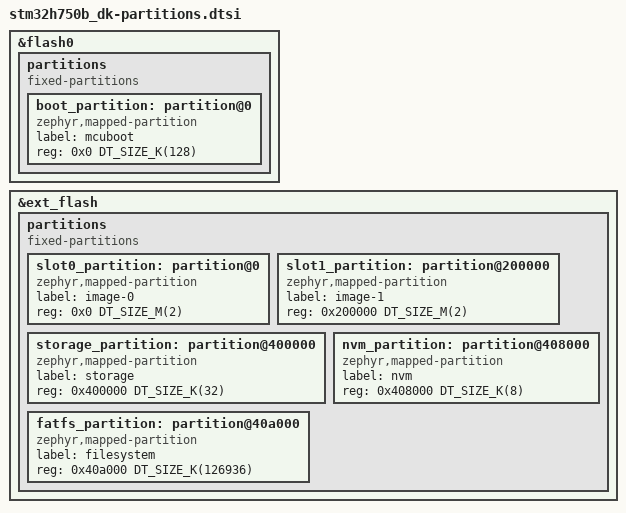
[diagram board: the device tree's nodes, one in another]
/* Partition layout for stm32h750b_dk: the flash memory map shared by the
 * bootloader and every application image. Generated by
 * tools/partition_layout.py; do not edit by hand -- re-run
 * `python3 tools/partition_layout.py --fix stm32h750b_dk` after changing
 * the upstream board geometry or tools/boards.toml.
 *
 * Board-specific overlay glue (delete-nodes, device enablement,
 * aliases/chosen) lives in dts/st/stm32h750b_dk.dtsi, which includes
 * this file.
 */

&flash0 {
	partitions {
		compatible = "fixed-partitions";
		#address-cells = <1>;
		#size-cells = <1>;
		ranges;

		boot_partition: partition@0 {
			compatible = "zephyr,mapped-partition";
			label = "mcuboot";
			reg = <0x0 DT_SIZE_K(128)>;
		};
	};
};

&ext_flash {
	partitions {
		compatible = "fixed-partitions";
		#address-cells = <1>;
		#size-cells = <1>;
		ranges;

		slot0_partition: partition@0 {
			compatible = "zephyr,mapped-partition";
			label = "image-0";
			reg = <0x0 DT_SIZE_M(2)>;
		};

		slot1_partition: partition@200000 {
			compatible = "zephyr,mapped-partition";
			label = "image-1";
			reg = <0x200000 DT_SIZE_M(2)>;
		};

		storage_partition: partition@400000 {
			compatible = "zephyr,mapped-partition";
			label = "storage";
			reg = <0x400000 DT_SIZE_K(32)>;
		};

		nvm_partition: partition@408000 {
			compatible = "zephyr,mapped-partition";
			label = "nvm";
			reg = <0x408000 DT_SIZE_K(8)>;
		};

		fatfs_partition: partition@40a000 {
			compatible = "zephyr,mapped-partition";
			label = "filesystem";
			reg = <0x40a000 DT_SIZE_K(126936)>;
		};
	};
};
